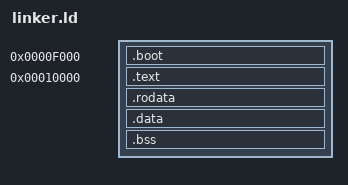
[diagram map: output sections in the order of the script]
OUTPUT_FORMAT(elf32-i386)

STARTUP_PHYSICAL_ADDRESS = 0x0000F000;
KERNEL_PHYSICAL_ADDRESS  = 0x00010000;
KERNEL_VIRTUAL_ADDRESS   = 0xC0000000;

SECTIONS
{
	. = STARTUP_PHYSICAL_ADDRESS;

	.boot :
	{
		obj/init/startup.o
	}

	. = KERNEL_PHYSICAL_ADDRESS;
	. += KERNEL_VIRTUAL_ADDRESS;

	.text ALIGN(4K) : AT(ADDR(.text) - KERNEL_VIRTUAL_ADDRESS)
	{
		*(.text)
	}

	.rodata ALIGN(4K) : AT(ADDR(.rodata) - KERNEL_VIRTUAL_ADDRESS)
	{
		*(.rodata)
	}

	.data ALIGN(4K) : AT(ADDR(.data) - KERNEL_VIRTUAL_ADDRESS)
	{
		*(.data)
	}

	BSS_SECTION_START = .;

	.bss ALIGN(4K) : AT(ADDR(.bss) - KERNEL_VIRTUAL_ADDRESS)
	{
		*(.bss)
	}

	BSS_SECTION_END = .;
	KERNEL_VIRTUAL_ADDRESS_END = .;
}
